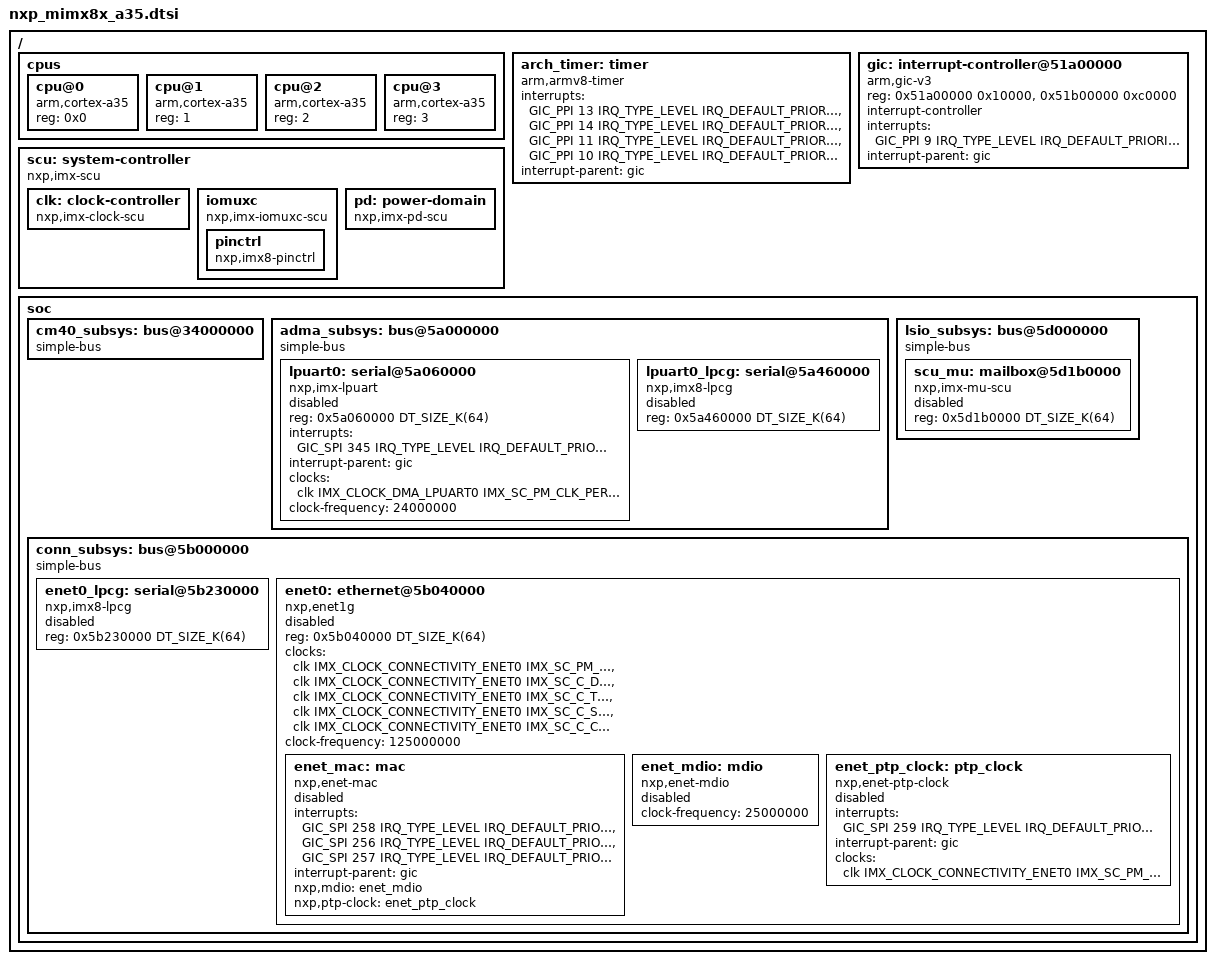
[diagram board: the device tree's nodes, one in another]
/*
 * Copyright (c) 2021
 *
 * SPDX-License-Identifier: Apache-2.0
 */

#include <mem.h>
#include <freq.h>
#include <arm64/armv8-a.dtsi>
#include <zephyr/dt-bindings/firmware/imx/rsrc.h>
#include <zephyr/dt-bindings/clock/imx_scu_clock.h>
#include <zephyr/dt-bindings/interrupt-controller/arm-gic.h>

/ {
	cpus {
		#address-cells = <1>;
		#size-cells = <0>;

		cpu@0 {
			device_type = "cpu";
			compatible = "arm,cortex-a35";
			reg = <0x0>;
		};
		cpu@1 {
			device_type = "cpu";
			compatible = "arm,cortex-a35";
			reg = <1>;
		};

		cpu@2 {
			device_type = "cpu";
			compatible = "arm,cortex-a35";
			reg = <2>;
		};

		cpu@3 {
			device_type = "cpu";
			compatible = "arm,cortex-a35";
			reg = <3>;
		};
	};

	arch_timer: timer {
		compatible = "arm,armv8-timer";
		interrupts = <GIC_PPI 13 IRQ_TYPE_LEVEL
			      IRQ_DEFAULT_PRIORITY>,
			     <GIC_PPI 14 IRQ_TYPE_LEVEL
			      IRQ_DEFAULT_PRIORITY>,
			     <GIC_PPI 11 IRQ_TYPE_LEVEL
			      IRQ_DEFAULT_PRIORITY>,
			     <GIC_PPI 10 IRQ_TYPE_LEVEL
			      IRQ_DEFAULT_PRIORITY>;
		interrupt-parent = <&gic>;
	};

	gic: interrupt-controller@51a00000 {
		compatible = "arm,gic-v3", "arm,gic";
		reg = <0x51a00000 0x10000>, /* GIC Dist */
		      <0x51b00000 0xc0000>; /* GICR (RD_base + SGI_base) */
		interrupt-controller;
		#interrupt-cells = <4>;
		interrupts = <GIC_PPI 9 IRQ_TYPE_LEVEL IRQ_DEFAULT_PRIORITY>;
		interrupt-parent = <&gic>;
		status = "okay";
	};

	scu: system-controller {
		compatible = "nxp,imx-scu";

		clk: clock-controller {
			compatible = "nxp,imx-clock-scu";
			#clock-cells = <3>;
		};

		iomuxc: iomuxc {
			compatible = "nxp,imx-iomuxc-scu";
			pinctrl: pinctrl {
				compatible = "nxp,imx8-pinctrl";
			};
		};

		pd: power-domain {
			compatible = "nxp,imx-pd-scu";
		};
	};

	soc {
		cm40_subsys: bus@34000000 {
			compatible = "simple-bus";
			#address-cells = <1>;
			#size-cells = <1>;
			ranges = <0 0x34000000 0x4000000>;
		};

		adma_subsys: bus@5a000000 {
			compatible = "simple-bus";
			ranges = <0 0x5a000000 0x1000000>;
			#address-cells = <1>;
			#size-cells = <1>;

			lpuart0: serial@5a060000 {
				compatible = "nxp,imx-lpuart", "nxp,kinetis-lpuart";
				reg = <0x5a060000 DT_SIZE_K(64)>;
				interrupts = <GIC_SPI 345 IRQ_TYPE_LEVEL IRQ_DEFAULT_PRIORITY>;
				interrupt-parent=<&gic>;
				clocks = <&clk IMX_CLOCK_DMA_LPUART0 IMX_SC_PM_CLK_PER 0>;
				clock-frequency = <24000000>;
				status = "disabled";
			};

			lpuart0_lpcg: serial@5a460000 {
				compatible = "nxp,imx8-lpcg";
				reg = <0x5a460000 DT_SIZE_K(64)>;
				status = "disabled";
			};
		};

		lsio_subsys: bus@5d000000 {
			compatible = "simple-bus";
			ranges = <0 0x5d000000 0x1000000>;
			#address-cells = <1>;
			#size-cells = <1>;

			/* LSIO MU0_A, used to interact with the SCFW */
			scu_mu: mailbox@5d1b0000 {
				compatible = "nxp,imx-mu-scu";
				reg = <0x5d1b0000 DT_SIZE_K(64)>;
				status = "disabled";
			};
		};

		conn_subsys: bus@5b000000 {
			compatible = "simple-bus";
			ranges = <0 0x5b000000 0x1000000>;
			#address-cells = <1>;
			#size-cells = <1>;

			enet0_lpcg: serial@5b230000 {
				compatible = "nxp,imx8-lpcg";
				reg = <0x5b230000 DT_SIZE_K(64)>;
				status = "disabled";
			};

			enet0: ethernet@5b040000 {
				compatible = "nxp,enet1g";
				reg = <0x5b040000 DT_SIZE_K(64)>;
				clocks = <&clk IMX_CLOCK_CONNECTIVITY_ENET0 IMX_SC_PM_CLK_PER 0>,
					<&clk IMX_CLOCK_CONNECTIVITY_ENET0 IMX_SC_C_DISABLE_50 1>,
					<&clk IMX_CLOCK_CONNECTIVITY_ENET0 IMX_SC_C_TXCLK 0>,
					<&clk IMX_CLOCK_CONNECTIVITY_ENET0 IMX_SC_C_SEL_125 1>,
					<&clk IMX_CLOCK_CONNECTIVITY_ENET0 IMX_SC_C_CLKDIV 0>;

				clock-frequency = <125000000>;
				status = "disabled";

				enet_mac: mac {
					compatible = "nxp,enet-mac";
					interrupts = <GIC_SPI 258 IRQ_TYPE_LEVEL IRQ_DEFAULT_PRIORITY>,
						<GIC_SPI 256 IRQ_TYPE_LEVEL IRQ_DEFAULT_PRIORITY>,
						<GIC_SPI 257 IRQ_TYPE_LEVEL IRQ_DEFAULT_PRIORITY>;
					interrupt-names = "ENET0_FRAME0", "ENET0_FRAME1",
										"ENET0_FRAME2";
					interrupt-parent=<&gic>;
					nxp,mdio = <&enet_mdio>;
					nxp,ptp-clock = <&enet_ptp_clock>;
					status = "disabled";
				};

				enet_mdio: mdio {
					compatible = "nxp,enet-mdio";
					#address-cells = <1>;
					#size-cells = <0>;
					clock-frequency = <25000000>;
					status = "disabled";
				};

				enet_ptp_clock: ptp_clock {
					compatible = "nxp,enet-ptp-clock";
					interrupts = <GIC_SPI 259 IRQ_TYPE_LEVEL IRQ_DEFAULT_PRIORITY>;
					interrupt-parent=<&gic>;
					clocks = <&clk IMX_CLOCK_CONNECTIVITY_ENET0 IMX_SC_PM_CLK_PER 0>;
					status = "disabled";
				};
			};
		};
	};
};
